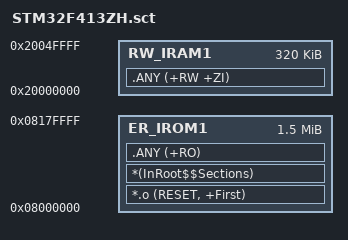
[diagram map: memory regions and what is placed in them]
; Flash 0x08000000..0x0817FFFF (1536 KiB).
; SRAM  0x20000000..0x2004FFFF (320 KiB), per ST F413 template.
LR_IROM1 0x08000000 0x00180000 {
  ER_IROM1 0x08000000 0x00180000 {
    *.o (RESET, +First)
    *(InRoot$$Sections)
    .ANY (+RO)
  }
  RW_IRAM1 0x20000000 0x00050000 {
    .ANY (+RW +ZI)
  }
}
